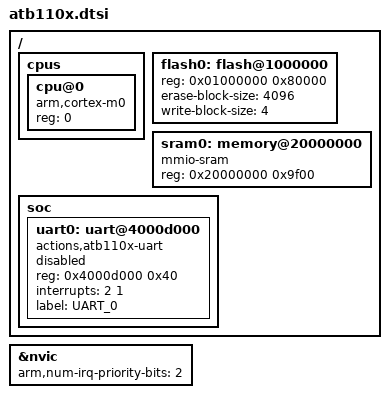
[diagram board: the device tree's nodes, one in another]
#include <arm/armv6-m.dtsi>

/ {
	cpus {
		#address-cells = <1>;
		#size-cells = <0>;

		cpu@0 {
			device_type = "cpu";
			compatible = "arm,cortex-m0";
			reg = <0>;
		};
	};

	flash0: flash@1000000 {
		reg = <0x01000000 0x80000>;
		erase-block-size = <4096>;
		write-block-size = <4>;
	};

	sram0: memory@20000000 {
		device_type = "memory";
		compatible = "mmio-sram";
		reg = <0x20000000 0x9f00>;
	};

	soc {
		uart0: uart@4000d000 {
			compatible = "actions,atb110x-uart";
			reg = <0x4000d000 0x40>;
			interrupts = <2 1>;
			status = "disabled";
			label = "UART_0";
		};
	};

};

&nvic {
	arm,num-irq-priority-bits = <2>;
};
